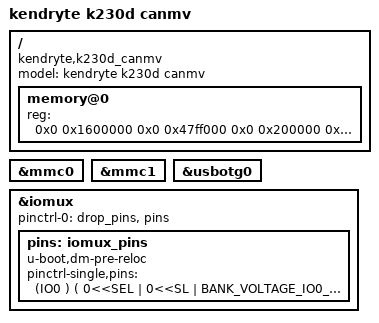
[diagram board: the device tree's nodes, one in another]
/* Copyright (c) 2023, Canaan Bright Sight Co., Ltd
 *
 * Redistribution and use in source and binary forms, with or without
 * modification, are permitted provided that the following conditions are met:
 * 1. Redistributions of source code must retain the above copyright
 * notice, this list of conditions and the following disclaimer.
 * 2. Redistributions in binary form must reproduce the above copyright
 * notice, this list of conditions and the following disclaimer in the
 * documentation and/or other materials provided with the distribution.
 *
 * THIS SOFTWARE IS PROVIDED BY THE COPYRIGHT HOLDERS AND
 * CONTRIBUTORS "AS IS" AND ANY EXPRESS OR IMPLIED WARRANTIES,
 * INCLUDING, BUT NOT LIMITED TO, THE IMPLIED WARRANTIES OF
 * MERCHANTABILITY AND FITNESS FOR A PARTICULAR PURPOSE ARE
 * DISCLAIMED. IN NO EVENT SHALL THE COPYRIGHT HOLDER OR
 * CONTRIBUTORS BE LIABLE FOR ANY DIRECT, INDIRECT, INCIDENTAL,
 * SPECIAL, EXEMPLARY, OR CONSEQUENTIAL DAMAGES (INCLUDING,
 * BUT NOT LIMITED TO, PROCUREMENT OF SUBSTITUTE GOODS OR
 * SERVICES; LOSS OF USE, DATA, OR PROFITS; OR BUSINESS
 * INTERRUPTION) HOWEVER CAUSED AND ON ANY THEORY OF LIABILITY,
 * WHETHER IN CONTRACT, STRICT LIABILITY, OR TORT (INCLUDING
 * NEGLIGENCE OR OTHERWISE) ARISING IN ANY WAY OUT OF THE USE
 * OF THIS SOFTWARE, EVEN IF ADVISED OF THE POSSIBILITY OF SUCH DAMAGE.
 */
/dts-v1/;
#include <dt-bindings/pinctrl/k230_evb.h>
#define BANK_VOLTAGE_IO0_IO1	 K230_MSC_1V8  // FIXED
#define BANK_VOLTAGE_IO2_IO13	 K230_MSC_3V3
#define BANK_VOLTAGE_IO14_IO25	 K230_MSC_3V3
#define BANK_VOLTAGE_IO26_IO37	 K230_MSC_3V3
#define BANK_VOLTAGE_IO38_IO49	 K230_MSC_3V3
#define BANK_VOLTAGE_IO50_IO61	 K230_MSC_3V3
#define BANK_VOLTAGE_IO62_IO63	 K230_MSC_3V3
#include "k230d.dtsi"

/ {
	model = "kendryte k230d canmv";
	compatible = "kendryte,k230d_canmv";

	memory@0 {
		device_type = "memory";
		reg = <
				0x0 0x1600000 0x0 0x47ff000  /*MEM_LINUX_SYS*/
				0x0 0x200000 0x0 0x13ff000  /*MEM_RTT_SYS*/
			  >;
	};
};

&mmc0 {
	status = "okay";
};

&mmc1 {
	status = "okay";
};

&usbotg0 {
	status = "okay";
};

&iomux {
	pinctrl-names = "default";
	pinctrl-0 = <&drop_pins &pins>;

//	Please pay attention to the bank voltage! will damage the chip.
	pins: iomux_pins {
		u-boot,dm-pre-reloc;
		pinctrl-single,pins = <

		// SW3 KEY
		(IO0 ) ( 0<<SEL | 0<<SL | BANK_VOLTAGE_IO0_IO1 <<MSC | 1<<IE | 0<<OE | 1<<PU | 0<<PD | 2<<DS | 0<<ST )
		(IO1 ) ( 1<<SEL | 0<<SL | BANK_VOLTAGE_IO0_IO1 <<MSC | 1<<IE | 0<<OE | 1<<PU | 0<<PD | 2<<DS | 0<<ST )

		// JTAG
		(IO2 ) ( 1<<SEL | 0<<SL | BANK_VOLTAGE_IO2_IO13 <<MSC | 1<<IE | 0<<OE | 0<<PU | 1<<PD | 4<<DS | 1<<ST )
		(IO3 ) ( 1<<SEL | 0<<SL | BANK_VOLTAGE_IO2_IO13 <<MSC | 1<<IE | 0<<OE | 0<<PU | 0<<PD | 4<<DS | 0<<ST )
		(IO4 ) ( 1<<SEL | 0<<SL | BANK_VOLTAGE_IO2_IO13 <<MSC | 0<<IE | 1<<OE | 0<<PU | 0<<PD | 4<<DS | 0<<ST )
		(IO5 ) ( 1<<SEL | 0<<SL | BANK_VOLTAGE_IO2_IO13 <<MSC | 1<<IE | 0<<OE | 0<<PU | 0<<PD | 4<<DS | 0<<ST )
		(IO6 ) ( 1<<SEL | 0<<SL | BANK_VOLTAGE_IO2_IO13 <<MSC | 1<<IE | 0<<OE | 1<<PU | 0<<PD | 4<<DS | 0<<ST )

		// IIC4 -> CAM0
		(IO7 ) ( 2<<SEL | 0<<SL | BANK_VOLTAGE_IO2_IO13 <<MSC | 1<<IE | 1<<OE | 1<<PU | 0<<PD | 7<<DS | 1<<ST ) //GPIO7/PWM2/IIC4_SCL/TEST_PIN3/DI0
		(IO8 ) ( 2<<SEL | 0<<SL | BANK_VOLTAGE_IO2_IO13 <<MSC | 1<<IE | 1<<OE | 1<<PU | 0<<PD | 7<<DS | 1<<ST ) //GPIO8/PWM3/IIC4_SDA/TEST_PIN4/DI1
		// JP1-PIN14
		(IO10) ( 0<<SEL | 0<<SL | BANK_VOLTAGE_IO2_IO13 <<MSC | 1<<IE | 1<<OE | 0<<PU | 0<<PD | 8<<DS | 0<<ST )
		// JP1-PIN11
        (IO11) ( 0<<SEL | 0<<SL | BANK_VOLTAGE_IO2_IO13 <<MSC | 1<<IE | 1<<OE | 0<<PU | 0<<PD | 8<<DS | 0<<ST )
		// JP1-PIN20
        (IO12) ( 0<<SEL | 0<<SL | BANK_VOLTAGE_IO2_IO13 <<MSC | 1<<IE | 1<<OE | 0<<PU | 0<<PD | 8<<DS | 0<<ST )

		// M_CLK
		(IO13) ( 1<<SEL | 0<<SL | BANK_VOLTAGE_IO2_IO13 <<MSC | 0<<IE | 1<<OE | 0<<PU | 1<<PD | 4<<DS | 1<<ST )

		// JP1-PIN28
		(IO14) ( 0<<SEL | 0<<SL | BANK_VOLTAGE_IO14_IO25<<MSC | 1<<IE | 1<<OE | 0<<PU | 0<<PD | 15<<DS | 1<<ST ) //GPIO14/OSPI_CS/TEST_PIN5/QSPI0_CS0/DO3
		// JP1-PIN25
        (IO15) ( 0<<SEL | 0<<SL | BANK_VOLTAGE_IO14_IO25<<MSC | 1<<IE | 1<<OE | 0<<PU | 0<<PD | 15<<DS | 1<<ST )
		// JP1-PIN29
        (IO16) ( 0<<SEL | 0<<SL | BANK_VOLTAGE_IO14_IO25<<MSC | 1<<IE | 1<<OE | 0<<PU | 0<<PD | 15<<DS | 1<<ST )
		// JP1-PIN32
        (IO17) ( 0<<SEL | 0<<SL | BANK_VOLTAGE_IO14_IO25<<MSC | 1<<IE | 1<<OE | 0<<PU | 0<<PD | 15<<DS | 1<<ST )
		// JP1-PIN30
        (IO18) ( 0<<SEL | 0<<SL | BANK_VOLTAGE_IO14_IO25<<MSC | 1<<IE | 1<<OE | 0<<PU | 0<<PD | 15<<DS | 1<<ST )
		// JP1-PIN27
        (IO19) ( 0<<SEL | 0<<SL | BANK_VOLTAGE_IO14_IO25<<MSC | 1<<IE | 1<<OE | 0<<PU | 0<<PD | 15<<DS | 1<<ST )
		// CAM0_GPIO
        (IO20) ( 0<<SEL | 0<<SL | BANK_VOLTAGE_IO14_IO25<<MSC | 1<<IE | 1<<OE | 0<<PU | 0<<PD | 15<<DS | 1<<ST )
		// CAM1_GPIO
        (IO21) ( 0<<SEL | 0<<SL | BANK_VOLTAGE_IO14_IO25<<MSC | 1<<IE | 1<<OE | 0<<PU | 0<<PD | 15<<DS | 1<<ST )
		// TP_INT
        (IO22) ( 0<<SEL | 0<<SL | BANK_VOLTAGE_IO14_IO25<<MSC | 1<<IE | 0<<OE | 0<<PU | 0<<PD | 15<<DS | 1<<ST )
		// TP_RST
        (IO23) ( 0<<SEL | 0<<SL | BANK_VOLTAGE_IO14_IO25<<MSC | 0<<IE | 1<<OE | 0<<PU | 0<<PD | 15<<DS | 1<<ST )
		// LCD_RST
        (IO24) ( 0<<SEL | 0<<SL | BANK_VOLTAGE_IO14_IO25<<MSC | 0<<IE | 1<<OE | 0<<PU | 1<<PD | 7<<DS | 1<<ST )
		// LCD_EN
        (IO25) ( 0<<SEL | 0<<SL | BANK_VOLTAGE_IO14_IO25<<MSC | 0<<IE | 1<<OE | 0<<PU | 0<<PD | 7<<DS | 1<<ST )

		// SD
		(IO26) ( 1<<SEL | 0<<SL | BANK_VOLTAGE_IO26_IO37<<MSC | 0<<IE | 1<<OE | 0<<PU | 0<<PD | 7<<DS | 1<<ST )//clk
		(IO27) ( 1<<SEL | 0<<SL | BANK_VOLTAGE_IO26_IO37<<MSC | 1<<IE | 1<<OE | 0<<PU | 0<<PD | 7<<DS | 1<<ST ) //cmd
		(IO28) ( 1<<SEL | 0<<SL | BANK_VOLTAGE_IO26_IO37<<MSC | 1<<IE | 1<<OE | 0<<PU | 0<<PD | 7<<DS | 1<<ST ) //d0
		(IO29) ( 1<<SEL | 0<<SL | BANK_VOLTAGE_IO26_IO37<<MSC | 1<<IE | 1<<OE | 0<<PU | 0<<PD | 7<<DS | 1<<ST )
		(IO30) ( 1<<SEL | 0<<SL | BANK_VOLTAGE_IO26_IO37<<MSC | 1<<IE | 1<<OE | 0<<PU | 0<<PD | 7<<DS | 1<<ST )
		(IO31) ( 1<<SEL | 0<<SL | BANK_VOLTAGE_IO26_IO37<<MSC | 1<<IE | 1<<OE | 0<<PU | 0<<PD | 7<<DS | 1<<ST ) //d3

		(IO32) ( 2<<SEL | 0<<SL | BANK_VOLTAGE_IO26_IO37<<MSC | 0<<IE | 1<<OE | 0<<PU | 0<<PD | 4<<DS | 0<<ST )
		(IO33) ( 2<<SEL | 0<<SL | BANK_VOLTAGE_IO26_IO37<<MSC | 0<<IE | 1<<OE | 0<<PU | 0<<PD | 4<<DS | 0<<ST )
		(IO34) ( 2<<SEL | 0<<SL | BANK_VOLTAGE_IO26_IO37<<MSC | 1<<IE | 0<<OE | 0<<PU | 0<<PD | 4<<DS | 0<<ST )
		(IO35) ( 2<<SEL | 0<<SL | BANK_VOLTAGE_IO26_IO37<<MSC | 0<<IE | 1<<OE | 0<<PU | 0<<PD | 4<<DS | 0<<ST )

		// I2C3 -> TP
        (IO36) ( 1<<SEL | 0<<SL | BANK_VOLTAGE_IO26_IO37<<MSC | 1<<IE | 1<<OE | 1<<PU | 0<<PD | 7<<DS | 1<<ST )
		(IO37) ( 1<<SEL | 0<<SL | BANK_VOLTAGE_IO26_IO37<<MSC | 1<<IE | 1<<OE | 1<<PU | 0<<PD | 7<<DS | 1<<ST )

		// UART0
		(IO38) ( 1<<SEL | 0<<SL | BANK_VOLTAGE_IO38_IO49<<MSC | 0<<IE | 1<<OE | 0<<PU | 0<<PD | 7<<DS | 1<<ST )
		(IO39) ( 1<<SEL | 0<<SL | BANK_VOLTAGE_IO38_IO49<<MSC | 1<<IE | 0<<OE | 0<<PU | 0<<PD | 7<<DS | 1<<ST ) //GPIO39/UART0_RXD/TEST_PIN9/QSPI1_CLK/VSYNC0

		// IIC1 -> CAM
		(IO40) ( 2<<SEL | 0<<SL | BANK_VOLTAGE_IO38_IO49<<MSC | 1<<IE | 1<<OE | 1<<PU | 0<<PD | 7<<DS | 1<<ST )
		(IO41) ( 2<<SEL | 0<<SL | BANK_VOLTAGE_IO38_IO49<<MSC | 1<<IE | 1<<OE | 1<<PU | 0<<PD | 7<<DS | 1<<ST )

		// UART2
		(IO44) ( 1<<SEL | 0<<SL | BANK_VOLTAGE_IO38_IO49<<MSC | 0<<IE | 1<<OE | 0<<PU | 0<<PD | 7<<DS | 1<<ST )
		(IO45) ( 1<<SEL | 0<<SL | BANK_VOLTAGE_IO38_IO49<<MSC | 1<<IE | 0<<OE | 0<<PU | 0<<PD | 7<<DS | 1<<ST )

        // IIC0 -> CAM
		(IO48) ( 1<<SEL | 0<<SL | BANK_VOLTAGE_IO38_IO49<<MSC | 0<<IE | 1<<OE | 0<<PU | 0<<PD | 7<<DS | 1<<ST )
		(IO49) ( 1<<SEL | 0<<SL | BANK_VOLTAGE_IO38_IO49<<MSC | 1<<IE | 0<<OE | 0<<PU | 0<<PD | 7<<DS | 1<<ST )

        // JP1-PIN24
		(IO59) ( 0<<SEL | 0<<SL | BANK_VOLTAGE_IO50_IO61<<MSC | 1<<IE | 1<<OE | 1<<PU | 0<<PD | 7<<DS | 1<<ST )
        // JP1-PIN26
		(IO60) ( 0<<SEL | 0<<SL | BANK_VOLTAGE_IO50_IO61<<MSC | 1<<IE | 1<<OE | 1<<PU | 0<<PD | 7<<DS | 1<<ST )
		// JP1-PIN23
        (IO61) ( 0<<SEL | 0<<SL | BANK_VOLTAGE_IO50_IO61<<MSC | 1<<IE | 1<<OE | 1<<PU | 0<<PD | 7<<DS | 1<<ST )

		// M_CLK2 -> // JP1-PIN21
		(IO62) ( 1<<SEL | 0<<SL | BANK_VOLTAGE_IO62_IO63<<MSC | 0<<IE | 1<<OE | 0<<PU | 1<<PD | 4<<DS | 1<<ST )
		// M_CLK2 -> // JP1-PIN22
        (IO63) ( 1<<SEL | 0<<SL | BANK_VOLTAGE_IO62_IO63<<MSC | 0<<IE | 1<<OE | 0<<PU | 1<<PD | 4<<DS | 1<<ST )
		>;
	};
};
